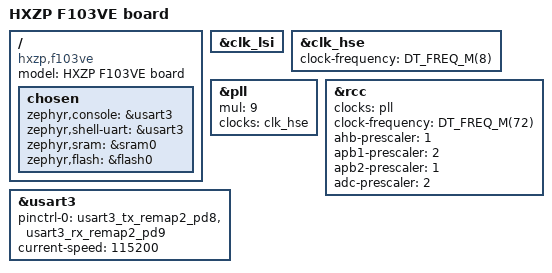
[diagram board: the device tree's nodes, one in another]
/*
 * Copyright (c) 2017 Linaro Limited
 *
 * SPDX-License-Identifier: Apache-2.0
 */

/dts-v1/;
#include <st/f1/stm32f103Xe.dtsi>
#include <st/f1/stm32f103v(c-d-e)tx-pinctrl.dtsi>
#include <zephyr/dt-bindings/input/input-event-codes.h>
#include <zephyr/dt-bindings/led/led.h>

/ {
	model = "HXZP F103VE board";
	compatible = "hxzp,f103ve";

	chosen {
		zephyr,console = &usart3;
		zephyr,shell-uart = &usart3;
		zephyr,sram = &sram0;
		zephyr,flash = &flash0;
	};
};

&clk_lsi {
	status = "okay";
};

&clk_hse {
	// hse-bypass;
	clock-frequency = <DT_FREQ_M(8)>;	/* On-board 8MHz clock */
	status = "okay";
};

&pll {
	mul = <9>;
	clocks = <&clk_hse>;
	status = "okay";
};

&rcc {
	clocks = <&pll>;
	clock-frequency = <DT_FREQ_M(72)>;
	ahb-prescaler = <1>;
	apb1-prescaler = <2>;
	apb2-prescaler = <1>;
	adc-prescaler = <2>;
};

&usart3 {
	pinctrl-0 = <&usart3_tx_remap2_pd8 &usart3_rx_remap2_pd9>;
	pinctrl-names = "default";
	current-speed = <115200>;
	status = "okay";
};

// &i2c1 {
// 	pinctrl-0 = <&i2c1_scl_remap1_pb8 &i2c1_sda_remap1_pb9>;
// 	pinctrl-names = "default";
// 	clock-frequency = <I2C_BITRATE_FAST>;
// 	status = "disabled";
// };

// &spi1 {
// 	pinctrl-0 = <&spi1_sck_master_pa5 &spi1_miso_master_pa6 &spi1_mosi_master_pa7>;
// 	pinctrl-names = "default";
// 	cs-gpios = <&gpiob 6 (GPIO_ACTIVE_LOW | GPIO_PULL_UP)>;
// 	status = "disabled";
// };

// &spi2 {
// 	pinctrl-0 = <&spi2_nss_master_pb12 &spi2_sck_master_pb13
// 		     &spi2_miso_master_pb14 &spi2_mosi_master_pb15>;
// 	pinctrl-names = "default";
// 	status = "disabled";
// };

// &timers1 {
// 	st,prescaler = <10000>;
// 	status = "disabled";

// 	pwm1: pwm {
// 		status = "okay";
// 		pinctrl-0 = <&tim1_ch1_pwm_out_pa8>;
// 		pinctrl-names = "default";
// 	};
// };

// &timers2 {
// 	st,prescaler = <255>;
// 	status = "disabled";

// 	pwm2: pwm {
// 		status = "okay";
// 		pinctrl-0 = <&tim2_ch2_pwm_in_pa1>;
// 		pinctrl-names = "default";
// 	};
// };

// &iwdg {
// 	status = "disabled";
// };

// &rtc {
// 	clocks = <&rcc STM32_CLOCK_BUS_APB1 0x10000000>,
// 		 <&rcc STM32_SRC_LSI RTC_SEL(2)>;
// 	status = "disabled";
// };

// &adc1 {
// 	pinctrl-0 = <&adc1_in0_pa0>;
// 	pinctrl-names = "default";
// 	status = "disabled";
// };

// &flash0 {
// 	partitions {
// 		compatible = "fixed-partitions";
// 		#address-cells = <1>;
// 		#size-cells = <1>;

// 		/* Set 2KB of storage at the end of flash */
// 		storage_partition: partition@1f800 {
// 			label = "storage";
// 			reg = <0x0001f800 DT_SIZE_K(2)>;
// 		};
// 	};
// };
